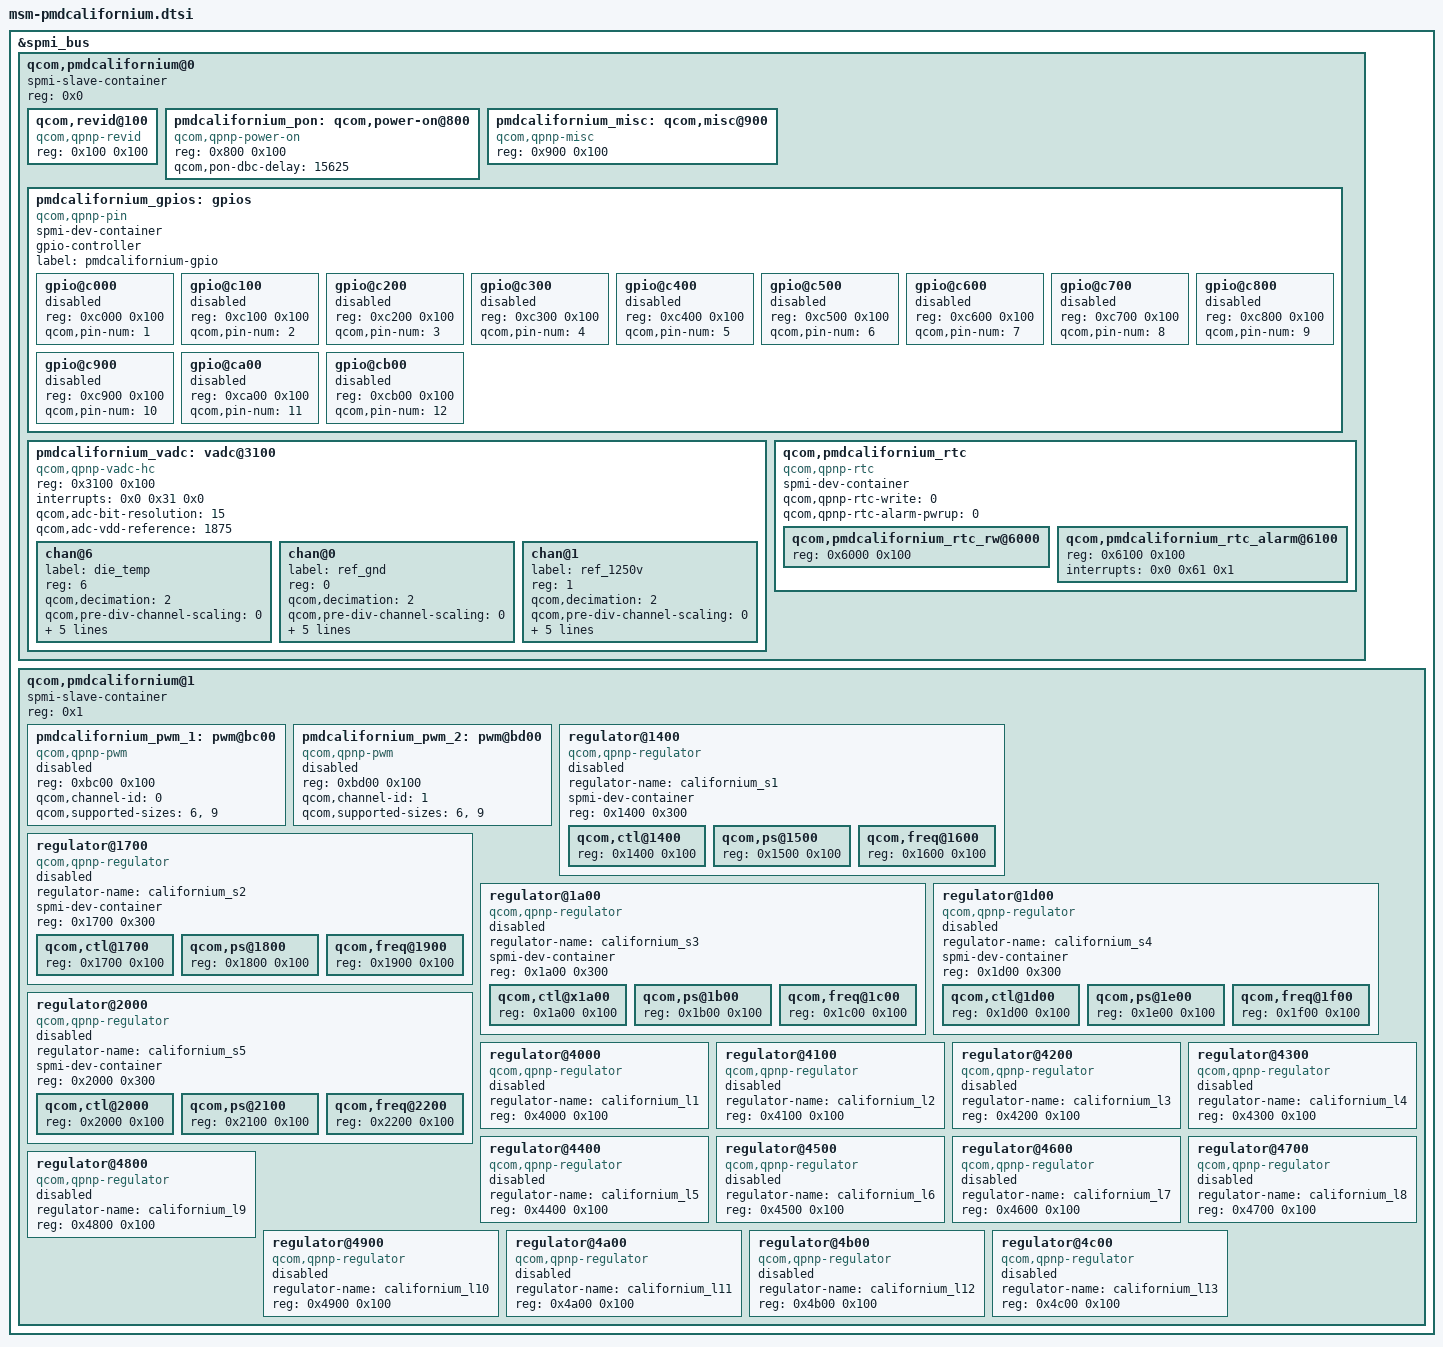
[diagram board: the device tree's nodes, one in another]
/* Copyright (c) 2015-2016, The Linux Foundation. All rights reserved.
 *
 * This program is free software; you can redistribute it and/or modify
 * it under the terms of the GNU General Public License version 2 and
 * only version 2 as published by the Free Software Foundation.
 *
 * This program is distributed in the hope that it will be useful,
 * but WITHOUT ANY WARRANTY; without even the implied warranty of
 * MERCHANTABILITY or FITNESS FOR A PARTICULAR PURPOSE.  See the
 * GNU General Public License for more details.
 */

&spmi_bus {
	qcom,pmdcalifornium@0 {
		spmi-slave-container;
		reg = <0x0>;
		#address-cells = <1>;
		#size-cells = <1>;

		qcom,revid@100 {
			compatible = "qcom,qpnp-revid";
			reg = <0x100 0x100>;
		};

		pmdcalifornium_pon: qcom,power-on@800 {
			compatible = "qcom,qpnp-power-on";
			reg = <0x800 0x100>;
			qcom,pon-dbc-delay = <15625>;

		};

		pmdcalifornium_misc: qcom,misc@900 {
			compatible = "qcom,qpnp-misc";
			reg = <0x900 0x100>;
		};

		pmdcalifornium_gpios: gpios {
			spmi-dev-container;
			compatible = "qcom,qpnp-pin";
			gpio-controller;
			#gpio-cells = <2>;
			#address-cells = <1>;
			#size-cells = <1>;
			label = "pmdcalifornium-gpio";

			gpio@c000 {
				reg = <0xc000 0x100>;
				qcom,pin-num = <1>;
				status = "disabled";
			};

			gpio@c100 {
				reg = <0xc100 0x100>;
				qcom,pin-num = <2>;
				status = "disabled";
			};

			gpio@c200 {
				reg = <0xc200 0x100>;
				qcom,pin-num = <3>;
				status = "disabled";
			};

			gpio@c300 {
				reg = <0xc300 0x100>;
				qcom,pin-num = <4>;
				status = "disabled";
			};

			gpio@c400 {
				reg = <0xc400 0x100>;
				qcom,pin-num = <5>;
				status = "disabled";
			};

			gpio@c500 {
				reg = <0xc500 0x100>;
				qcom,pin-num = <6>;
				status = "disabled";
			};

			gpio@c600 {
				reg = <0xc600 0x100>;
				qcom,pin-num = <7>;
				status = "disabled";
			};

			gpio@c700 {
				reg = <0xc700 0x100>;
				qcom,pin-num = <8>;
				status = "disabled";
			};

			gpio@c800 {
				reg = <0xc800 0x100>;
				qcom,pin-num = <9>;
				status = "disabled";
			};

			gpio@c900 {
				reg = <0xc900 0x100>;
				qcom,pin-num = <10>;
				status = "disabled";
			};

			gpio@ca00 {
				reg = <0xca00 0x100>;
				qcom,pin-num = <11>;
				status = "disabled";
			};

			gpio@cb00 {
				reg = <0xcb00 0x100>;
				qcom,pin-num = <12>;
				status = "disabled";
			};
		};

		pmdcalifornium_vadc: vadc@3100 {
			compatible = "qcom,qpnp-vadc-hc";
			reg = <0x3100 0x100>;
			#address-cells = <1>;
			#size-cells = <0>;
			interrupts = <0x0 0x31 0x0>;
			interrupt-names = "eoc-int-en-set";
			qcom,adc-bit-resolution = <15>;
			qcom,adc-vdd-reference = <1875>;

			chan@6 {
				label = "die_temp";
				reg = <6>;
				qcom,decimation = <2>;
				qcom,pre-div-channel-scaling = <0>;
				qcom,calibration-type = "absolute";
				qcom,scale-function = <3>;
				qcom,hw-settle-time = <0>;
				qcom,fast-avg-setup = <0>;
				qcom,cal-val = <0>;
			};

			chan@0 {
				label = "ref_gnd";
				reg = <0>;
				qcom,decimation = <2>;
				qcom,pre-div-channel-scaling = <0>;
				qcom,calibration-type = "absolute";
				qcom,scale-function = <0>;
				qcom,hw-settle-time = <0>;
				qcom,fast-avg-setup = <0>;
				qcom,cal-val = <0>;
			};

			chan@1 {
				label = "ref_1250v";
				reg = <1>;
				qcom,decimation = <2>;
				qcom,pre-div-channel-scaling = <0>;
				qcom,calibration-type = "absolute";
				qcom,scale-function = <0>;
				qcom,hw-settle-time = <0>;
				qcom,fast-avg-setup = <0>;
				qcom,cal-val = <0>;
			};
		};

		qcom,pmdcalifornium_rtc {
			spmi-dev-container;
			compatible = "qcom,qpnp-rtc";
			#address-cells = <1>;
			#size-cells = <1>;
			qcom,qpnp-rtc-write = <0>;
			qcom,qpnp-rtc-alarm-pwrup = <0>;

			qcom,pmdcalifornium_rtc_rw@6000 {
				reg = <0x6000 0x100>;
			};

			qcom,pmdcalifornium_rtc_alarm@6100 {
				reg = <0x6100 0x100>;
				interrupts = <0x0 0x61 0x1>;
			};
		};
	};

	qcom,pmdcalifornium@1 {
		spmi-slave-container;
		reg = <0x1>;
		#address-cells = <1>;
		#size-cells = <1>;

		pmdcalifornium_pwm_1: pwm@bc00 {
			compatible = "qcom,qpnp-pwm";
			reg = <0xbc00 0x100>;
			reg-names = "qpnp-lpg-channel-base";
			qcom,channel-id = <0>;
			qcom,supported-sizes = <6>, <9>;
			#pwm-cells = <2>;
			status = "disabled";
		};

		pmdcalifornium_pwm_2: pwm@bd00 {
			compatible = "qcom,qpnp-pwm";
			reg = <0xbd00 0x100>;
			reg-names = "qpnp-lpg-channel-base";
			qcom,channel-id = <1>;
			qcom,supported-sizes = <6>, <9>;
			#pwm-cells = <2>;
			status = "disabled";
		};

		regulator@1400 {
			compatible = "qcom,qpnp-regulator";
			regulator-name = "californium_s1";
			spmi-dev-container;
			#address-cells = <1>;
			#size-cells = <1>;
			reg = <0x1400 0x300>;
			status = "disabled";

			qcom,ctl@1400 {
				reg = <0x1400 0x100>;
			};
			qcom,ps@1500 {
				reg = <0x1500 0x100>;
			};
			qcom,freq@1600 {
				reg = <0x1600 0x100>;
			};
		};

		regulator@1700 {
			compatible = "qcom,qpnp-regulator";
			regulator-name = "californium_s2";
			spmi-dev-container;
			#address-cells = <1>;
			#size-cells = <1>;
			reg = <0x1700 0x300>;
			status = "disabled";

			qcom,ctl@1700 {
				reg = <0x1700 0x100>;
			};
			qcom,ps@1800 {
				reg = <0x1800 0x100>;
			};
			qcom,freq@1900 {
				reg = <0x1900 0x100>;
			};
		};

		regulator@1a00 {
			compatible = "qcom,qpnp-regulator";
			regulator-name = "californium_s3";
			spmi-dev-container;
			#address-cells = <1>;
			#size-cells = <1>;
			reg = <0x1a00 0x300>;
			status = "disabled";

			qcom,ctl@x1a00 {
				reg = <0x1a00 0x100>;
			};
			qcom,ps@1b00 {
				reg = <0x1b00 0x100>;
			};
			qcom,freq@1c00 {
				reg = <0x1c00 0x100>;
			};
		};

		regulator@1d00 {
			compatible = "qcom,qpnp-regulator";
			regulator-name = "californium_s4";
			spmi-dev-container;
			#address-cells = <1>;
			#size-cells = <1>;
			reg = <0x1d00 0x300>;
			status = "disabled";

			qcom,ctl@1d00 {
				reg = <0x1d00 0x100>;
			};
			qcom,ps@1e00 {
				reg = <0x1e00 0x100>;
			};
			qcom,freq@1f00 {
				reg = <0x1f00 0x100>;
			};
		};

		regulator@2000 {
			compatible = "qcom,qpnp-regulator";
			regulator-name = "californium_s5";
			spmi-dev-container;
			#address-cells = <1>;
			#size-cells = <1>;
			reg = <0x2000 0x300>;
			status = "disabled";

			qcom,ctl@2000 {
				reg = <0x2000 0x100>;
			};
			qcom,ps@2100 {
				reg = <0x2100 0x100>;
			};
			qcom,freq@2200 {
				reg = <0x2200 0x100>;
			};
		};

		regulator@4000 {
			compatible = "qcom,qpnp-regulator";
			regulator-name = "californium_l1";
			reg = <0x4000 0x100>;
			status = "disabled";
		};

		regulator@4100 {
			compatible = "qcom,qpnp-regulator";
			regulator-name = "californium_l2";
			reg = <0x4100 0x100>;
			status = "disabled";
		};

		regulator@4200 {
			compatible = "qcom,qpnp-regulator";
			regulator-name = "californium_l3";
			reg = <0x4200 0x100>;
			status = "disabled";
		};

		regulator@4300 {
			compatible = "qcom,qpnp-regulator";
			regulator-name = "californium_l4";
			reg = <0x4300 0x100>;
			status = "disabled";
		};

		regulator@4400 {
			compatible = "qcom,qpnp-regulator";
			regulator-name = "californium_l5";
			reg = <0x4400 0x100>;
			status = "disabled";
		};

		regulator@4500 {
			compatible = "qcom,qpnp-regulator";
			regulator-name = "californium_l6";
			reg = <0x4500 0x100>;
			status = "disabled";
		};

		regulator@4600 {
			compatible = "qcom,qpnp-regulator";
			regulator-name = "californium_l7";
			reg = <0x4600 0x100>;
			status = "disabled";
		};

		regulator@4700 {
			compatible = "qcom,qpnp-regulator";
			regulator-name = "californium_l8";
			reg = <0x4700 0x100>;
			status = "disabled";
		};

		regulator@4800 {
			compatible = "qcom,qpnp-regulator";
			regulator-name = "californium_l9";
			reg = <0x4800 0x100>;
			status = "disabled";
		};

		regulator@4900 {
			compatible = "qcom,qpnp-regulator";
			regulator-name = "californium_l10";
			reg = <0x4900 0x100>;
			status = "disabled";
		};

		regulator@4a00 {
			compatible = "qcom,qpnp-regulator";
			regulator-name = "californium_l11";
			reg = <0x4a00 0x100>;
			status = "disabled";
		};

		regulator@4b00 {
			compatible = "qcom,qpnp-regulator";
			regulator-name = "californium_l12";
			reg = <0x4b00 0x100>;
			status = "disabled";
		};

		regulator@4c00 {
			compatible = "qcom,qpnp-regulator";
			regulator-name = "californium_l13";
			reg = <0x4c00 0x100>;
			status = "disabled";
		};
	};
};
